# PIC32CX1025MTSH128S1 device description
Architecture: CORTEX-M4; Family: PIC32CXMT; Series: PIC32CXMTSH
Registers are 32-bit, read-write, no defined reset value unless marked. A register's access mark holds for its fields unless they carry their own. Offsets are from the block's base; [hi:lo] are bit positions; {n}, {i} and the like mark numbered series; 'fields as' and 'values as' point back to an identical list.

## SFR — Special Function Register
Instances: SFR 0x40050400
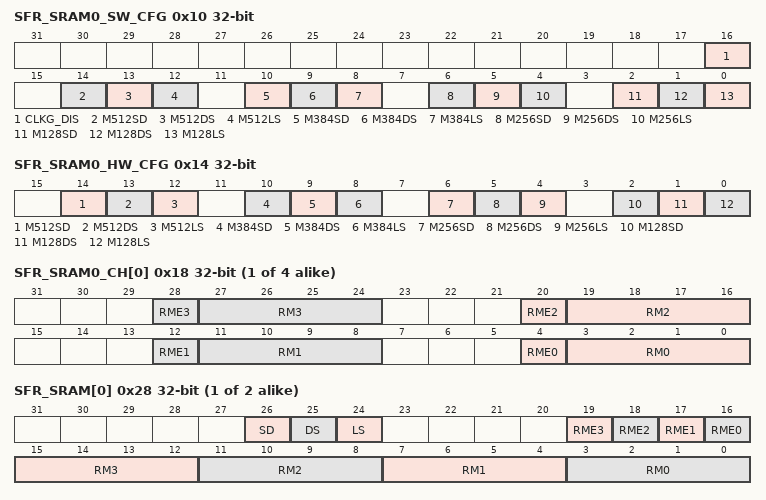
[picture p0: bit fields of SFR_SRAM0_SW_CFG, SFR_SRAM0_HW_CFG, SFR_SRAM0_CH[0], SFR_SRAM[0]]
0x10 SFR_SRAM0_SW_CFG — SRAM0 Software Config Register
  [16] CLKG_DIS — Clock Gating Disable
  [14] M512SD — 512 KB Shutdown Mode
  [13] M512DS — 512 KB Deep Sleep Mode
  [12] M512LS — 512 KB Light Sleep Mode
  [10] M384SD — 384 KB Shutdown Mode
  [9] M384DS — 384 KB Deep Sleep Mode
  [8] M384LS — 384 KB Light Sleep Mode
  [6] M256SD — 256 KB Shutdown Mode
  [5] M256DS — 256 KB Deep Sleep Mode
  [4] M256LS — 256 KB Light Sleep Mode
  [2] M128SD — 128 KB Shutdown Mode
  [1] M128DS — 128 KB Deep Sleep Mode
  [0] M128LS — 128 KB Light Sleep Mode
0x14 SFR_SRAM0_HW_CFG ro — SRAM0 Hardware Status Register
  [14] M512SD — 512 KB Shutdown Mode
  [13] M512DS — 512 KB Deep Sleep Mode
  [12] M512LS — 512 KB Light Sleep Mode
  [10] M384SD — 384 KB Shutdown Mode
  [9] M384DS — 384 KB Deep Sleep Mode
  [8] M384LS — 384 KB Light Sleep Mode
  [6] M256SD — 256 KB Shutdown Mode
  [5] M256DS — 256 KB Deep Sleep Mode
  [4] M256LS — 256 KB Light Sleep Mode
  [2] M128SD — 128 KB Shutdown Mode
  [1] M128DS — 128 KB Deep Sleep Mode
  [0] M128LS — 128 KB Light Sleep Mode
{0x18+4i} SFR_SRAM0_CH[{i}] (i=0..3) — SRAM0 Read Margin Register Channel
  [8n+4] RME{n} (n=0..3) — Read Margin Enable
  [8n+3:8n] RM{n} (n=0..3) — Read Margin
{0x28+4i} SFR_SRAM[{i}] (i=0..1) — SRAM Configuration Register
  [26] SD — Shutdown Mode
  [25] DS — Deep Sleep Mode
  [24] LS — Light Sleep Mode
  [n+16] RME{n} (n=0..3) — Read Margin Enable
  [4n+3:4n] RM{n} (n=0..3) — Read Margin
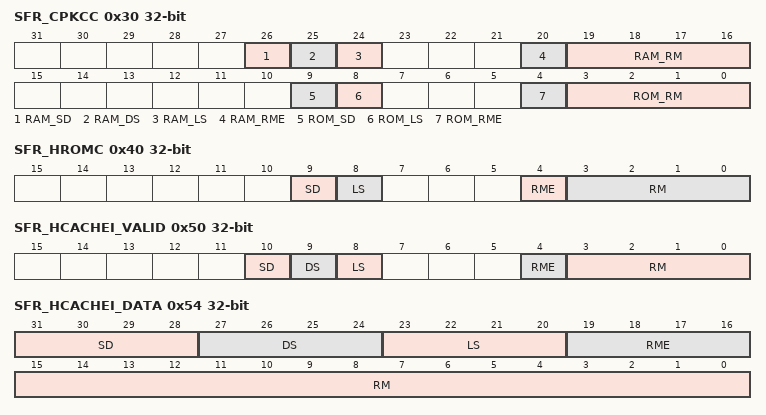
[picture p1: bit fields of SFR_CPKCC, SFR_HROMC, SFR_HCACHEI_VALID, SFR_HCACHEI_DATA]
0x30 SFR_CPKCC — CPKCC Memory Configuration Register
  [26] RAM_SD — Shutdown Mode
  [25] RAM_DS — RAM Deep Sleep Mode
  [24] RAM_LS — RAM Light Sleep Mode
  [20] RAM_RME — RAM Read Margin Enable
  [19:16] RAM_RM — RAM Read Margin
  [9] ROM_SD — Shutdown Mode
  [8] ROM_LS — ROM Light Sleep Mode
  [4] ROM_RME — ROM Read Margin Enable
  [3:0] ROM_RM — ROM Read Margin
0x40 SFR_HROMC — HROMC Memory Configuration Register
  [9] SD — Shutdown Mode
  [8] LS — HROMC Light Sleep Mode
  [4] RME — Read Margin Enable
  [3:0] RM — Read Margin
0x50 SFR_HCACHEI_VALID — HCACHEI Valid Memory Configuration Register
  [10] SD — Shutdown Mode
  [9] DS — Deep Sleep Mode
  [8] LS — Light Sleep Mode
  [4] RME — Read Margin Enable
  [3:0] RM — Read Margin
0x54 SFR_HCACHEI_DATA — HCACHEI Data Memory Configuration Register
  [31:28] SD — Shutdown Mode
  [27:24] DS — Deep Sleep Mode
  [23:20] LS — Light Sleep Mode
  [19:16] RME — Read Margin Enable
  [15:0] RM — Read Margin
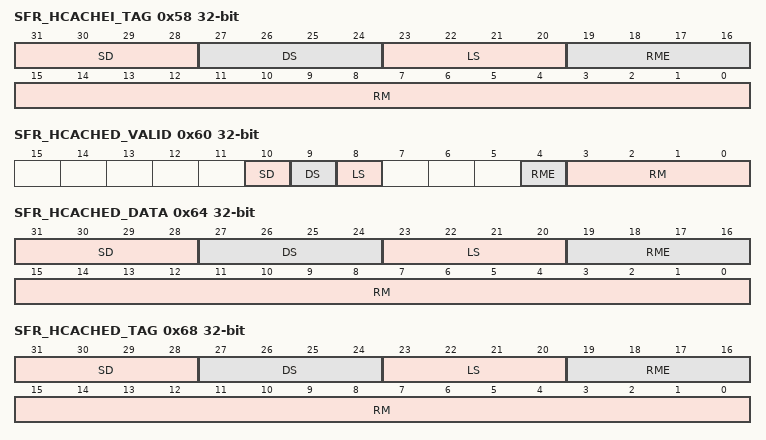
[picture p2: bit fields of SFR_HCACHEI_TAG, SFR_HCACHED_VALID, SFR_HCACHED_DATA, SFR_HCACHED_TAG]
0x58 SFR_HCACHEI_TAG — HCACHEI Tag Memory Configuration Register
  fields as SFR_HCACHEI_DATA
0x60 SFR_HCACHED_VALID — HCACHED Valid Memory Configuration Register
  fields as SFR_HCACHEI_VALID
0x64 SFR_HCACHED_DATA — HCACHED Data Memory Configuration Register
  fields as SFR_HCACHEI_DATA
0x68 SFR_HCACHED_TAG — HCACHEDTag Memory Configuration Register
  fields as SFR_HCACHEI_DATA
0x70 SFR_FLASH — Flash Memory Configuration Register
  [0] PATCH_BYPASS
0x80 SFR_OPT_LINK — Optical Link Register
  [0] CLK_SELECT — Clock Selection
0x90 SFR_JTAG — JTAG Register
  [0] JTAG_LOCK
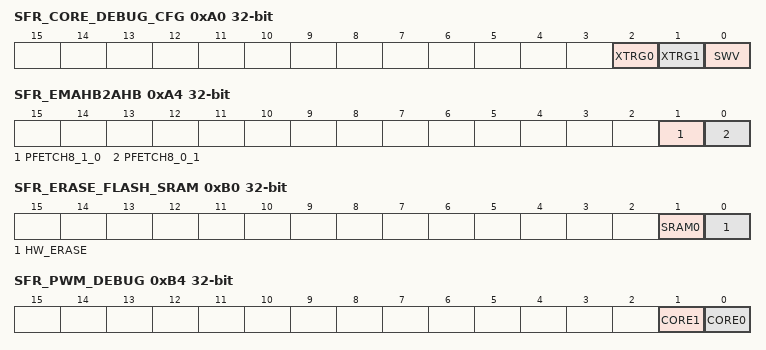
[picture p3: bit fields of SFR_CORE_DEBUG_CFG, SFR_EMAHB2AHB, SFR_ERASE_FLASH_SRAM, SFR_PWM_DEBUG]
0xA0 SFR_CORE_DEBUG_CFG — Core Debug Configuration Register
  [2] XTRG0 — From Core 0 to Core 1 Cross Triggering
  [1] XTRG1 — From Core 1 to Core 0 Cross Triggering
  [0] SWV — SWV Selection
0xA4 SFR_EMAHB2AHB — AHB2AHB Configuration Register
  [1] PFETCH8_1_0 — AHB MASTER1_0 Converter Prefetch
    0=INCR4 (INCR undefined burst converted to burst of 4 data.); 1=INCR8 (INCR undefined burst converted to burst of 8 data.)
  [0] PFETCH8_0_1 — AHB MASTER0_1 Converter Prefetch
    values as PFETCH8_1_0
0xA8 SFR_SECURE — Secure Register
  [0] ROM_ENA — ROM Access Enable
0xAC SFR_SECURE_BIT ro — Secure Bit Register
  [0] MODE_DIS — Secure Mode
0xB0 SFR_ERASE_FLASH_SRAM — Erase Flash/SRAM Register
  [1] SRAM0 — Erase SRAM0 Content
    0=NOT_DELETED (If HW_ERASE = 1, and HW erase signal assertion occurs, SRAM0 content is not deleted.); 1=DELETED (If HW_ERASE = 1, and HW erase signal assertion occurs, SRAM0 content is deleted.)
  [0] HW_ERASE — PB2/Peripherals or Hardware Erase Signal Assignment
    0=DISABLE (Hardware erase signal disabled. PB2 pin can be used in GPIO or Peripheral IO mode.); 1=ENABLE (Hardware erase signal enabled. PB2 pin is assigned to Flash erase function.)
0xB4 SFR_PWM_DEBUG — PWM Debug Register
  [1] CORE1 — Debug Information Propagation Mode
    0=NOT_SENT (Core x does not send the debug signal to the PWM.); 1=SENT (Core x sends the debug signal to PWM. Refer to "Debug Mode" in the section "Pulse Width Modulation Controller (PWM)" for details on configuring an action when the debug signal is active.)
  [0] CORE0 — Debug Information Propagation Mode
    values as CORE1
0xB8 SFR_FFPI ro — FFPI Register
  [0] MODE — FFPI Status
0xBC SFR_WAIT_MODE — Improved Wait Mode Register
  [0] CONTROL — Improved Wait Mode Control
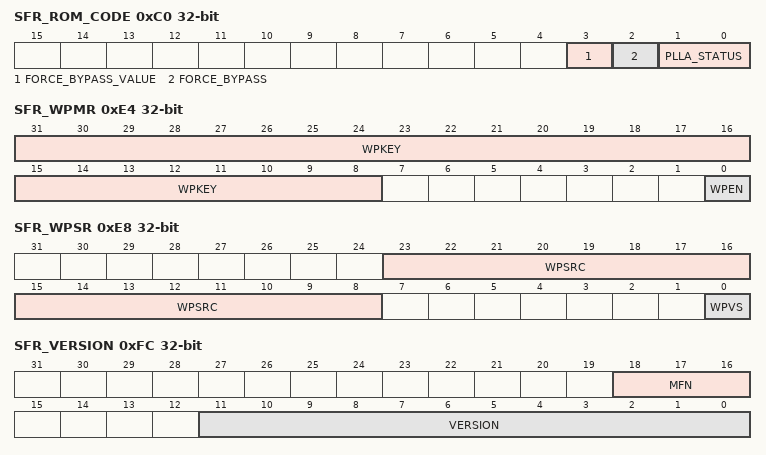
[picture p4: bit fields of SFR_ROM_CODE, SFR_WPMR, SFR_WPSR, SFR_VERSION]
0xC0 SFR_ROM_CODE ro — ROM Code Register
  [3] FORCE_BYPASS_VALUE, [2] FORCE_BYPASS, [1:0] PLLA_STATUS
0xE4 SFR_WPMR — Write Protection Mode Register
  [31:8] WPKEY — Write Protection Key
    0x534652=PASSWD (Writing any other value in this field aborts the write operation of the WPEN bit. Always reads as 0.)
  [0] WPEN — Write Protection Enable
0xE8 SFR_WPSR — Write Protection Status Register
  [23:8] WPSRC — Write Protection Source
  [0] WPVS — Write Protection Violation Status
0xF0 SFR_SPARE — Spare Register
  [31:0] VALUE — Spare
0xFC SFR_VERSION ro — Version Register
  [18:16] MFN — Metal Fix Number
  [11:0] VERSION — Version of the Hardware Module
